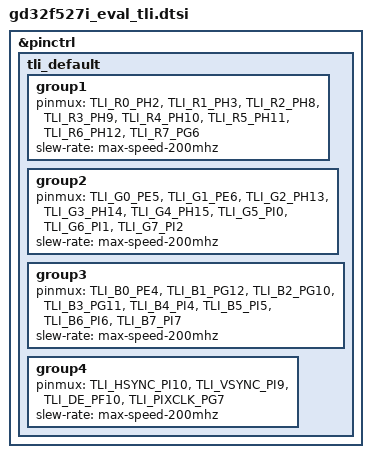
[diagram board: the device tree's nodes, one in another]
/*
 * Copyright (c) 2025 GigaDevice Semiconductor Inc.
 * SPDX-License-Identifier: Apache-2.0
 */

#include <dt-bindings/pinctrl/gd32f527i(m-s)xx-pinctrl.h>

&pinctrl {
    tli_default: tli_default {
		group1 {
			/* Red channel: R0-R7 */
			pinmux = <TLI_R0_PH2>,   /* PH2  - AF14 */
				 <TLI_R1_PH3>,   /* PH3  - AF14 */
				 <TLI_R2_PH8>,   /* PH8  - AF14 */
				 <TLI_R3_PH9>,   /* PH9  - AF14 */
				 <TLI_R4_PH10>,  /* PH10 - AF14 */
				 <TLI_R5_PH11>,  /* PH11 - AF14 */
				 <TLI_R6_PH12>,  /* PH12 - AF14 */
				 <TLI_R7_PG6>;   /* PG6  - AF14 */
			slew-rate = "max-speed-200mhz";
		};
		group2 {
			/* Green channel: G0-G7 */
			pinmux = <TLI_G0_PE5>,   /* PE5  - AF14 */
				 <TLI_G1_PE6>,   /* PE6  - AF14 */
				 <TLI_G2_PH13>,  /* PH13 - AF14 */
				 <TLI_G3_PH14>,  /* PH14 - AF14 */
				 <TLI_G4_PH15>,  /* PH15 - AF14 */
				 <TLI_G5_PI0>,   /* PI0  - AF14 */
				 <TLI_G6_PI1>,   /* PI1  - AF14 */
				 <TLI_G7_PI2>;   /* PI2  - AF14 */
			slew-rate = "max-speed-200mhz";
		};
		group3 {
			/* Blue channel: B0-B7 */
			pinmux = <TLI_B0_PE4>,   /* PE4  - AF14 */
				 <TLI_B1_PG12>,  /* PG12 - AF14 */
				 <TLI_B2_PG10>,  /* PG10 - AF14 */
				 <TLI_B3_PG11>,  /* PG11 - AF14 */
				 <TLI_B4_PI4>,   /* PI4  - AF14 */
				 <TLI_B5_PI5>,   /* PI5  - AF14 */
				 <TLI_B6_PI6>,   /* PI6  - AF14 */
				 <TLI_B7_PI7>;   /* PI7  - AF14 */
			slew-rate = "max-speed-200mhz";
		};
		group4 {
			/* Control signals */
			pinmux = <TLI_HSYNC_PI10>,  /* PI10 - Horizontal Sync */
				 <TLI_VSYNC_PI9>,   /* PI9  - Vertical Sync */
				 <TLI_DE_PF10>,     /* PF10 - Data Enable */
				 <TLI_PIXCLK_PG7>;  /* PG7  - Pixel Clock */
			slew-rate = "max-speed-200mhz";
		};
	};
};
